AUTOSAR XML (schema 4-0-3)
package /ComponentTypes
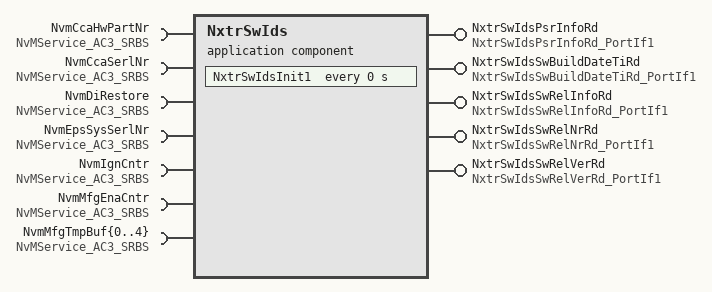
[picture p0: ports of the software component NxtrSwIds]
  application sw component type NxtrSwIds
    5 x provide port, all with server-com-spec{operation=Oper, queue-length=1}:
      NxtrSwIdsPsrInfoRd: provided-interface=NxtrSwIdsPsrInfoRd_PortIf1
      NxtrSwIdsSwBuildDateTiRd: provided-interface=NxtrSwIdsSwBuildDateTiRd_PortIf1
      NxtrSwIdsSwRelInfoRd: provided-interface=NxtrSwIdsSwRelInfoRd_PortIf1
      NxtrSwIdsSwRelNrRd: provided-interface=NxtrSwIdsSwRelNrRd_PortIf1
      NxtrSwIdsSwRelVerRd: provided-interface=NxtrSwIdsSwRelVerRd_PortIf1
    11 x require port, all with required-com-specs=[EraseBlock, GetErrorStatus, InvalidateNvBlock, ReadBlock, SetRamBlockStatus, WriteBlock], required-interface=NvMService_AC3_SRBS:
      NvmCcaHwPartNr
      NvmCcaSerlNr
      NvmDiRestore
      NvmEpsSysSerlNr
      NvmIgnCntr
      NvmMfgEnaCntr
      NvmMfgTmpBuf{0..4}
    behavior NxtrSwIds_InternalBehavior: data-type-mapping=Nexteer
      timing event CmnMfgSrv_InitEvent: start-on-event=NxtrSwIdsInit1, period=0
      5 x operation invoked event:
        OIT_NxtrSwIdsPsrInfoRd_Oper_NxtrSwIdsPsrInfoRd_Oper: start-on-event=NxtrSwIdsPsrInfoRd_Oper, operation=NxtrSwIdsPsrInfoRd.Oper
        OIT_NxtrSwIdsSwBuildDateTiRd_Oper_NxtrSwIdsSwBuildDateTiRd_Oper: start-on-event=NxtrSwIdsSwBuildDateTiRd_Oper, operation=NxtrSwIdsSwBuildDateTiRd.Oper
        OIT_NxtSwIdsSwRelInfoRd_Oper_NxtSwIdsSwRelInfoRd_Oper: start-on-event=NxtrSwIdsSwRelInfoRd_Oper, operation=NxtrSwIdsSwRelInfoRd.Oper
        OIT_NxtrSwIdsSwRelNrRd_Oper_NxtrSwIdsSwRelNrRd_Oper: start-on-event=NxtrSwIdsSwRelNrRd_Oper, operation=NxtrSwIdsSwRelNrRd.Oper
        OIT_NxtrSwIdsSwRelVerRd_Oper_NxtrSwIdsSwRelVerRd_Oper: start-on-event=NxtrSwIdsSwRelVerRd_Oper, operation=NxtrSwIdsSwRelVerRd.Oper
      6 x runnable:
        NxtrSwIdsInit1
        NxtrSwIdsPsrInfoRd_Oper
        NxtrSwIdsSwBuildDateTiRd_Oper
        NxtrSwIdsSwRelInfoRd_Oper
        NxtrSwIdsSwRelNrRd_Oper
        NxtrSwIdsSwRelVerRd_Oper
  swc implementation NxtrSwIds_Implementation: behavior=NxtrSwIds_InternalBehavior
    code-descriptors:
      code Default: artifact-descriptors=autosar-engineering-object={short-label=Default, category=SWSRC}
